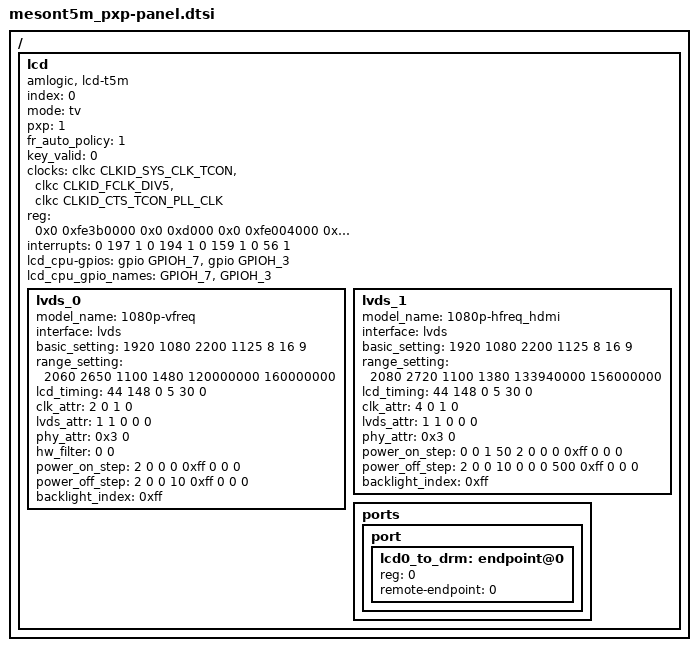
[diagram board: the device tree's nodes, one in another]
// SPDX-License-Identifier: (GPL-2.0+ OR MIT)
/*
 * Copyright (c) 2019 Amlogic, Inc. All rights reserved.
 */

/ {
	lcd:lcd {
		compatible = "amlogic, lcd-t5m";
		status = "okay";
		index = <0>;
		mode = "tv";
		pxp = <1>;
		fr_auto_policy = <1>; /* 0=disable, 1=60/50hz, 2=60/50/48hz */
		key_valid = <0>;
		clocks = <&clkc CLKID_SYS_CLK_TCON
				&clkc CLKID_FCLK_DIV5
				&clkc CLKID_CTS_TCON_PLL_CLK>;
		clock-names = "tcon_gate",
				"fclk_div5",
				"clk_tcon";
		reg = <0x0 0xfe3b0000 0x0 0xd000   /* tcon */
			0x0 0xfe004000 0x0 0x70    /* periphs */
			0x0 0xfe002000 0x0 0xa0>;  /* reset */
		interrupts = <0 197 1
			0 194 1
			0 159 1
			0 56 1>;
		interrupt-names = "vsync","vsync2","vbyone","tcon";
		//memory-region = <&lcd_tcon_reserved>;

		/* power type:(0=cpu_gpio, 2=signal, 3=extern, 0xff=ending) */
		/* power index:(gpios_index, or extern_index, 0xff=invalid) */
		/* power value:(0=output low, 1=output high, 2=input) */
		/* power delay:(unit in ms) */
		lcd_cpu-gpios = < &gpio GPIOH_7 GPIO_ACTIVE_HIGH
			&gpio GPIOH_3 GPIO_ACTIVE_HIGH>;
		lcd_cpu_gpio_names = "GPIOH_7","GPIOH_3";

		lvds_0{
			model_name = "1080p-vfreq";
			interface = "lvds"; /*lcd_interface(lvds, vbyone)*/
			basic_setting = <
				1920 1080 /*h_active, v_active*/
				2200 1125 /*h_period, v_period*/
				8      /*lcd_bits */
				16 9>; /*screen_widht, screen_height*/
			range_setting = <
				2060 2650  /*h_period_min,max*/
				1100 1480  /*v_period_min,max*/
				120000000 160000000>; /*pclk_min,max*/
			lcd_timing = <
				44 148 0  /*hs_width, hs_bp, hs_pol*/
				5  30 0>; /*vs_width, vs_bp, vs_pol*/
			clk_attr = <
				2 /*fr_adj_type
				   *(0=clk, 1=htotal, 2=vtotal, 3=auto_range,
				   * 4=hdmi_mode)
				   */
				0 /*clk_ss_level*/
				1 /*clk_auto_generate*/
				0>; /*pixel_clk(unit in Hz)*/
			lvds_attr = <
				1  /*lvds_repack*/
				1  /*dual_port*/
				0  /*pn_swap*/
				0  /*port_swap*/
				0>; /*lane_reverse*/
			phy_attr=<0x3 0>; /*vswing_level, preem_level*/
			hw_filter=<0 0>;  /* filter_time, filter_cnt*/

			/* power step: type, index, value, delay(ms) */
			power_on_step = <
				2 0 0 0   /*signal enable*/
				0xff 0 0 0>; /*ending*/
			power_off_step = <
				2 0 0 10  /*signal disable*/
				0xff 0 0 0>; /*ending*/
			backlight_index = <0xff>;
		};
		lvds_1{
			model_name = "1080p-hfreq_hdmi";
			interface = "lvds"; /*lcd_interface(lvds, vbyone)*/
			basic_setting = <
				1920 1080 /*h_active, v_active*/
				2200 1125 /*h_period, v_period*/
				8      /*lcd_bits*/
				16 9>; /*screen_widht, screen_height*/
			range_setting = <
				2080 2720 /*h_period min, max*/
				1100 1380 /*v_period min, max*/
				133940000 156000000>; /*pclk_min, max*/
			lcd_timing = <
				44 148 0   /*hs_width, hs_bp, hs_pol*/
				5  30  0>; /*vs_width, vs_bp, vs_pol*/
			clk_attr = <
				4 /*fr_adj_type
				   *(0=clk, 1=htotal, 2=vtotal, 3=auto_range,
				   * 4=hdmi_mode)
				   */
				0 /*clk_ss_level */
				1 /*clk_auto_generate*/
				0>; /*pixel_clk(unit in Hz)*/
			lvds_attr = <
				1 /*lvds_repack*/
				1 /*dual_port*/
				0 /*pn_swap*/
				0 /*port_swap*/
				0>; /*lane_reverse*/
			phy_attr=<0x3 0>; /*vswing_level, preem_level*/

			/* power step: type, index, value, delay(ms) */
			power_on_step = <
				0 0 1 50   /*panel power*/
				2 0 0 0   /*signal enable*/
				0xff 0 0 0>; /*ending*/
			power_off_step = <
				2 0 0 10  /*signal disable*/
				0 0 0 500   /*panel power*/
				0xff 0 0 0>; /*ending*/
			backlight_index = <0xff>;
		};
		ports {
			port {
				#address-cells = <1>;
				#size-cells = <0>;
				lcd0_to_drm: endpoint@0 {
					reg = <0>;
					remote-endpoint = <0>;
				};
			};
		};
	};

}; /* end of / */

